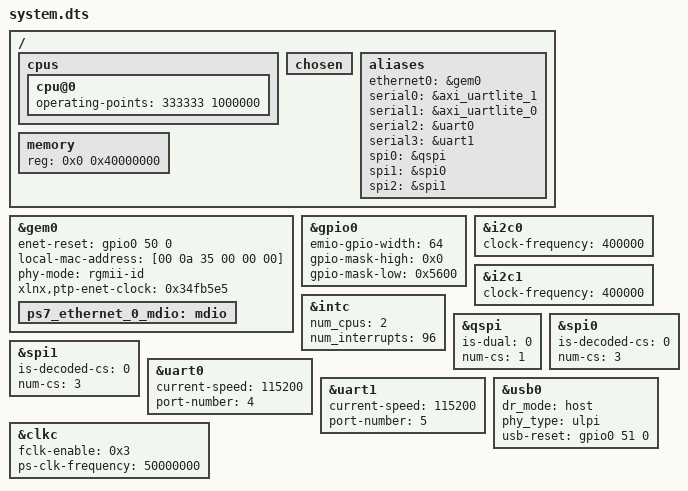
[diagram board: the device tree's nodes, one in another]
/*
 * CAUTION: This file is automatically generated by Xilinx.
 * Version:  
 * Today is: Mon Sep 28 14:59:03 2020
*/


/dts-v1/;
/include/ "zynq-7000.dtsi"
/include/ "pl.dtsi"
/ {
	cpus {
		cpu@0 {
			operating-points = <333333 1000000>;
		};
	};
	chosen {
	};
	aliases {
		ethernet0 = &gem0;
		serial0 = &axi_uartlite_1;
		serial1 = &axi_uartlite_0;
		serial2 = &uart0;
		serial3 = &uart1;
		spi0 = &qspi;
		spi1 = &spi0;
		spi2 = &spi1;
	};
	memory {
		device_type = "memory";
		reg = <0x0 0x40000000>;
	};
};
&gem0 {
	enet-reset = <&gpio0 50 0>;
	local-mac-address = [00 0a 35 00 00 00];
	phy-mode = "rgmii-id";
	status = "okay";
	xlnx,ptp-enet-clock = <0x34fb5e5>;
	ps7_ethernet_0_mdio: mdio {
		#address-cells = <1>;
		#size-cells = <0>;
	};
};
&gpio0 {
	emio-gpio-width = <64>;
	gpio-mask-high = <0x0>;
	gpio-mask-low = <0x5600>;
};
&i2c0 {
	clock-frequency = <400000>;
	status = "okay";
};
&i2c1 {
	clock-frequency = <400000>;
	status = "okay";
};
&intc {
	num_cpus = <2>;
	num_interrupts = <96>;
};
&qspi {
	is-dual = <0>;
	num-cs = <1>;
	status = "okay";
};
&spi0 {
	is-decoded-cs = <0>;
	num-cs = <3>;
	status = "okay";
};
&spi1 {
	is-decoded-cs = <0>;
	num-cs = <3>;
	status = "okay";
};
&uart0 {
	current-speed = <115200>;
	device_type = "serial";
	port-number = <4>;
	status = "okay";
};
&uart1 {
	current-speed = <115200>;
	device_type = "serial";
	port-number = <5>;
	status = "okay";
};
&usb0 {
	dr_mode = "host";
	phy_type = "ulpi";
	status = "okay";
	usb-reset = <&gpio0 51 0>;
};
&clkc {
	fclk-enable = <0x3>;
	ps-clk-frequency = <50000000>;
};
